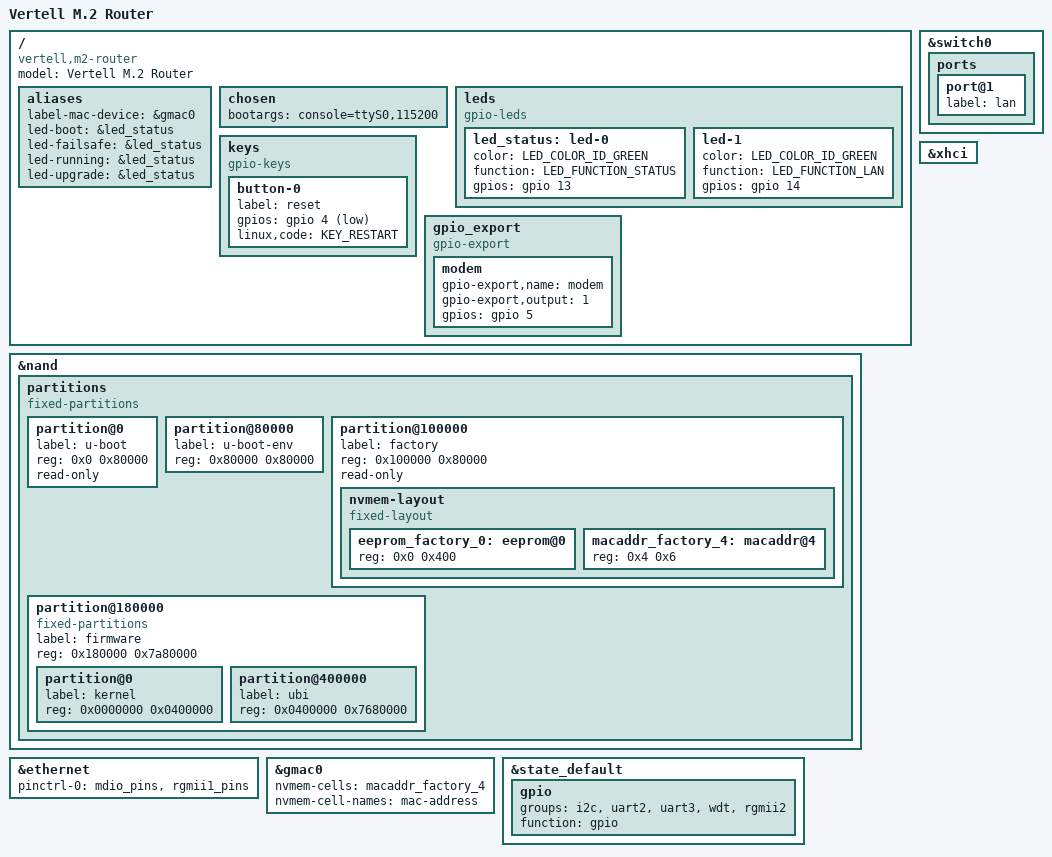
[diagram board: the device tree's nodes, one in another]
// SPDX-License-Identifier: GPL-2.0-or-later OR MIT

#include "mt7621.dtsi"

#include <dt-bindings/gpio/gpio.h>
#include <dt-bindings/input/input.h>
#include <dt-bindings/leds/common.h>

/ {
	compatible = "vertell,m2-router", "mediatek,mt7621-soc";
	model = "Vertell M.2 Router";

	aliases {
		label-mac-device = &gmac0;
		led-boot = &led_status;
		led-failsafe = &led_status;
		led-running = &led_status;
		led-upgrade = &led_status;
	};

	chosen {
		bootargs = "console=ttyS0,115200";
	};

	leds {
		compatible = "gpio-leds";

		led_status: led-0 {
			color = <LED_COLOR_ID_GREEN>;
			function = LED_FUNCTION_STATUS;
			gpios = <&gpio 13 GPIO_ACTIVE_HIGH>;
		};

		led-1 {
			color = <LED_COLOR_ID_GREEN>;
			function = LED_FUNCTION_LAN;
			gpios = <&gpio 14 GPIO_ACTIVE_HIGH>;
		};
	};

	keys {
		compatible = "gpio-keys";

		button-0 {
			label = "reset";
			gpios = <&gpio 4 GPIO_ACTIVE_LOW>;
			linux,code = <KEY_RESTART>;
		};
	};

	gpio_export {
		compatible = "gpio-export";
		#size-cells = <0>;

		modem {
			gpio-export,name = "modem";
			gpio-export,output = <1>;
			gpios = <&gpio 5 GPIO_ACTIVE_HIGH>;
		};
	};
};

&nand {
	status = "okay";
	/* 128MB nAND */
	partitions {
		compatible = "fixed-partitions";
		#address-cells = <1>;
		#size-cells = <1>;

		partition@0 {
			label = "u-boot";
			reg = <0x0 0x80000>;
			read-only;
		};

		partition@80000 {
			label = "u-boot-env";
			reg = <0x80000 0x80000>;
		};

		partition@100000 {
			label = "factory";
			reg = <0x100000 0x80000>;
			read-only;

			nvmem-layout {
				compatible = "fixed-layout";
				#address-cells = <1>;
				#size-cells = <1>;

				eeprom_factory_0: eeprom@0 {
					reg = <0x0 0x400>;
				};

				macaddr_factory_4: macaddr@4 {
					reg = <0x4 0x6>;
				};
			};
		};

		partition@180000 {
			label = "firmware";
			reg = <0x180000 0x7a80000>;
			
			compatible = "fixed-partitions";
			#address-cells = <1>;
			#size-cells = <1>;

			partition@0 {
				label = "kernel";
				reg = <0x0000000 0x0400000>;
			};

			partition@400000 {
				label = "ubi";
				reg = <0x0400000 0x7680000>;
			};
		};
	};
};

&ethernet {
        pinctrl-0 = <&mdio_pins>, <&rgmii1_pins>;
};

&gmac0 {
	nvmem-cells = <&macaddr_factory_4>;
	nvmem-cell-names = "mac-address";
};


&switch0 {
	ports {
		port@1 {
			status = "okay";
			label = "lan";
		};
	};
};

&state_default {
	gpio {
		groups = "i2c", "uart2", "uart3", "wdt", "rgmii2";
		function = "gpio";
	};
};

&xhci {
	status = "okay";
};
